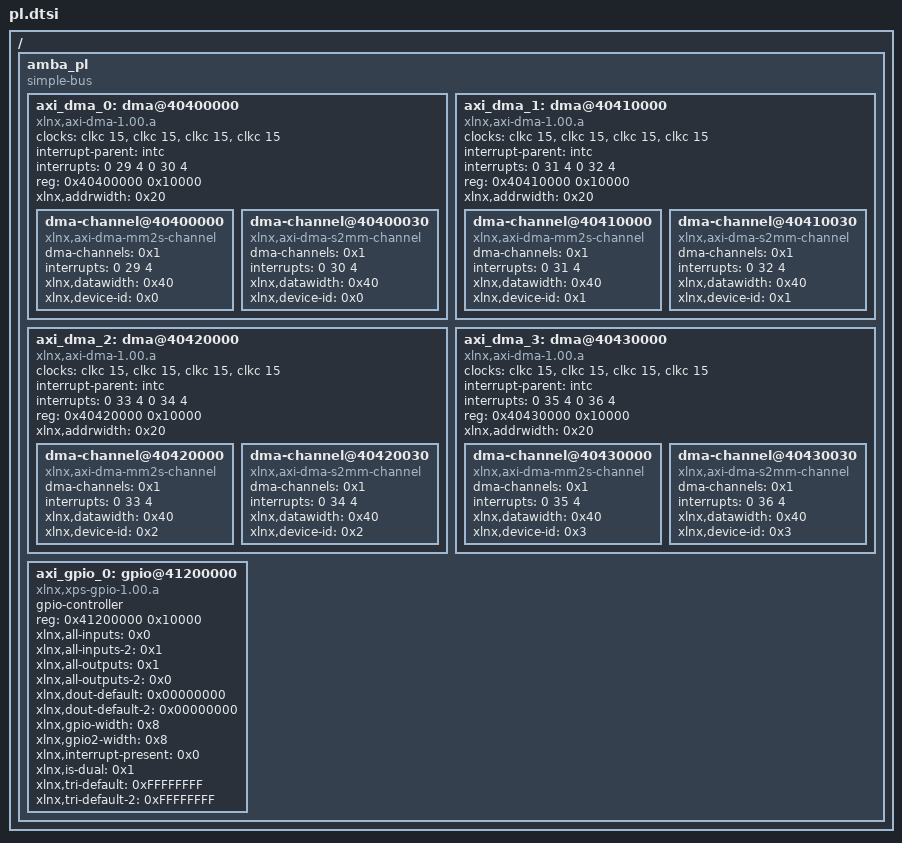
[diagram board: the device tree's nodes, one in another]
/*
 * CAUTION: This file is automatically generated by Xilinx.
 * Version:  
 * Today is: Thu Mar 23 11:33:24 2017
*/


/ {
	amba_pl: amba_pl {
		#address-cells = <1>;
		#size-cells = <1>;
		compatible = "simple-bus";
		ranges ;
		axi_dma_0: dma@40400000 {
			#dma-cells = <1>;
			clock-names = "s_axi_lite_aclk", "m_axi_sg_aclk", "m_axi_mm2s_aclk", "m_axi_s2mm_aclk";
			clocks = <&clkc 15>, <&clkc 15>, <&clkc 15>, <&clkc 15>;
			compatible = "xlnx,axi-dma-1.00.a";
			interrupt-parent = <&intc>;
			interrupts = <0 29 4 0 30 4>;
			reg = <0x40400000 0x10000>;
			xlnx,addrwidth = <0x20>;
			dma-channel@40400000 {
				compatible = "xlnx,axi-dma-mm2s-channel";
				dma-channels = <0x1>;
				interrupts = <0 29 4>;
				xlnx,datawidth = <0x40>;
				xlnx,device-id = <0x0>;
			};
			dma-channel@40400030 {
				compatible = "xlnx,axi-dma-s2mm-channel";
				dma-channels = <0x1>;
				interrupts = <0 30 4>;
				xlnx,datawidth = <0x40>;
				xlnx,device-id = <0x0>;
			};
		};
		axi_dma_1: dma@40410000 {
			#dma-cells = <1>;
			clock-names = "s_axi_lite_aclk", "m_axi_sg_aclk", "m_axi_mm2s_aclk", "m_axi_s2mm_aclk";
			clocks = <&clkc 15>, <&clkc 15>, <&clkc 15>, <&clkc 15>;
			compatible = "xlnx,axi-dma-1.00.a";
			interrupt-parent = <&intc>;
			interrupts = <0 31 4 0 32 4>;
			reg = <0x40410000 0x10000>;
			xlnx,addrwidth = <0x20>;
			dma-channel@40410000 {
				compatible = "xlnx,axi-dma-mm2s-channel";
				dma-channels = <0x1>;
				interrupts = <0 31 4>;
				xlnx,datawidth = <0x40>;
				xlnx,device-id = <0x1>;
			};
			dma-channel@40410030 {
				compatible = "xlnx,axi-dma-s2mm-channel";
				dma-channels = <0x1>;
				interrupts = <0 32 4>;
				xlnx,datawidth = <0x40>;
				xlnx,device-id = <0x1>;
			};
		};
		axi_dma_2: dma@40420000 {
			#dma-cells = <1>;
			clock-names = "s_axi_lite_aclk", "m_axi_sg_aclk", "m_axi_mm2s_aclk", "m_axi_s2mm_aclk";
			clocks = <&clkc 15>, <&clkc 15>, <&clkc 15>, <&clkc 15>;
			compatible = "xlnx,axi-dma-1.00.a";
			interrupt-parent = <&intc>;
			interrupts = <0 33 4 0 34 4>;
			reg = <0x40420000 0x10000>;
			xlnx,addrwidth = <0x20>;
			dma-channel@40420000 {
				compatible = "xlnx,axi-dma-mm2s-channel";
				dma-channels = <0x1>;
				interrupts = <0 33 4>;
				xlnx,datawidth = <0x40>;
				xlnx,device-id = <0x2>;
			};
			dma-channel@40420030 {
				compatible = "xlnx,axi-dma-s2mm-channel";
				dma-channels = <0x1>;
				interrupts = <0 34 4>;
				xlnx,datawidth = <0x40>;
				xlnx,device-id = <0x2>;
			};
		};
		axi_dma_3: dma@40430000 {
			#dma-cells = <1>;
			clock-names = "s_axi_lite_aclk", "m_axi_sg_aclk", "m_axi_mm2s_aclk", "m_axi_s2mm_aclk";
			clocks = <&clkc 15>, <&clkc 15>, <&clkc 15>, <&clkc 15>;
			compatible = "xlnx,axi-dma-1.00.a";
			interrupt-parent = <&intc>;
			interrupts = <0 35 4 0 36 4>;
			reg = <0x40430000 0x10000>;
			xlnx,addrwidth = <0x20>;
			dma-channel@40430000 {
				compatible = "xlnx,axi-dma-mm2s-channel";
				dma-channels = <0x1>;
				interrupts = <0 35 4>;
				xlnx,datawidth = <0x40>;
				xlnx,device-id = <0x3>;
			};
			dma-channel@40430030 {
				compatible = "xlnx,axi-dma-s2mm-channel";
				dma-channels = <0x1>;
				interrupts = <0 36 4>;
				xlnx,datawidth = <0x40>;
				xlnx,device-id = <0x3>;
			};
		};
		axi_gpio_0: gpio@41200000 {
			#gpio-cells = <2>;
			compatible = "xlnx,xps-gpio-1.00.a";
			gpio-controller ;
			reg = <0x41200000 0x10000>;
			xlnx,all-inputs = <0x0>;
			xlnx,all-inputs-2 = <0x1>;
			xlnx,all-outputs = <0x1>;
			xlnx,all-outputs-2 = <0x0>;
			xlnx,dout-default = <0x00000000>;
			xlnx,dout-default-2 = <0x00000000>;
			xlnx,gpio-width = <0x8>;
			xlnx,gpio2-width = <0x8>;
			xlnx,interrupt-present = <0x0>;
			xlnx,is-dual = <0x1>;
			xlnx,tri-default = <0xFFFFFFFF>;
			xlnx,tri-default-2 = <0xFFFFFFFF>;
		};
	};
};
